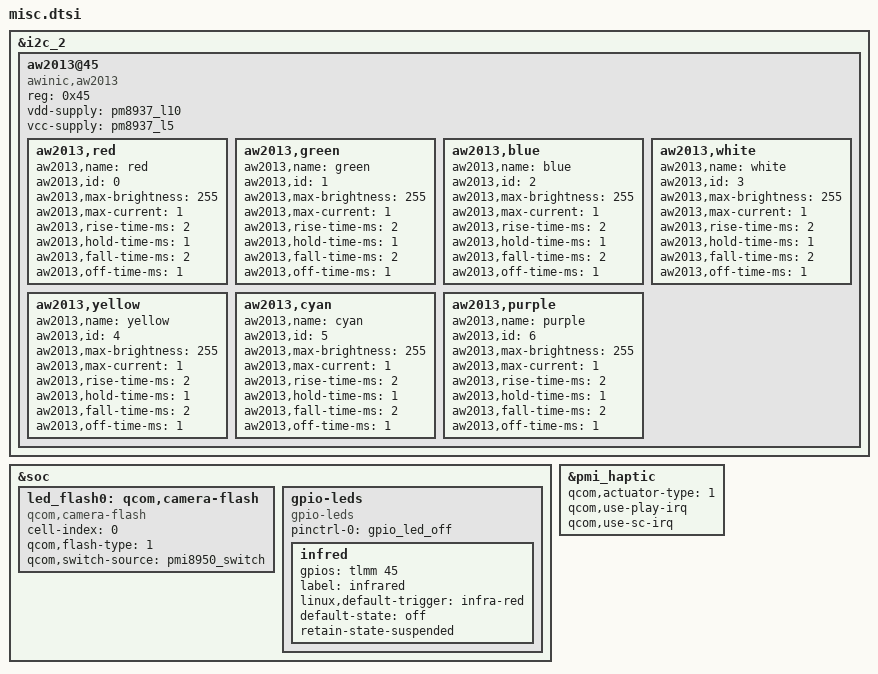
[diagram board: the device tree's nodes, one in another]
/* FROM: S88536AA2.dtsi */
&i2c_2  {
	aw2013@45 {
		compatible = "awinic,aw2013";
		reg = <0x45>;
		vdd-supply = <&pm8937_l10>; //Power supply needed to power up the device
		vcc-supply = <&pm8937_l5>; //Power source required to power up i2c bus

		aw2013,red {
			aw2013,name = "red";
			aw2013,id = <0>;
			aw2013,max-brightness = <255>;
			aw2013,max-current = <1>;
			aw2013,rise-time-ms = <2>;
			aw2013,hold-time-ms = <1>;
			aw2013,fall-time-ms = <2>;
			aw2013,off-time-ms = <1>;
		};
		aw2013,green {
			aw2013,name = "green";
			aw2013,id = <1>;
			aw2013,max-brightness = <255>;
			aw2013,max-current = <1>;
			aw2013,rise-time-ms = <2>;
			aw2013,hold-time-ms = <1>;
			aw2013,fall-time-ms = <2>;
			aw2013,off-time-ms = <1>;
		};
		aw2013,blue {
			aw2013,name = "blue";
			aw2013,id = <2>;
			aw2013,max-brightness = <255>;
			aw2013,max-current = <1>;
			aw2013,rise-time-ms = <2>;
			aw2013,hold-time-ms = <1>;
			aw2013,fall-time-ms = <2>;
			aw2013,off-time-ms = <1>;
		};
		aw2013,white {
			aw2013,name = "white";
			aw2013,id = <3>;
			aw2013,max-brightness = <255>;
			aw2013,max-current = <1>;
			aw2013,rise-time-ms = <2>;
			aw2013,hold-time-ms = <1>;
			aw2013,fall-time-ms = <2>;
			aw2013,off-time-ms = <1>;
		};
		aw2013,yellow {
			aw2013,name = "yellow";
			aw2013,id = <4>;
			aw2013,max-brightness = <255>;
			aw2013,max-current = <1>;
			aw2013,rise-time-ms = <2>;
			aw2013,hold-time-ms = <1>;
			aw2013,fall-time-ms = <2>;
			aw2013,off-time-ms = <1>;
		};
		aw2013,cyan {
			aw2013,name = "cyan";
			aw2013,id = <5>;
			aw2013,max-brightness = <255>;
			aw2013,max-current = <1>;
			aw2013,rise-time-ms = <2>;
			aw2013,hold-time-ms = <1>;
			aw2013,fall-time-ms = <2>;
			aw2013,off-time-ms = <1>;
		};
		aw2013,purple {
			aw2013,name = "purple";
			aw2013,id = <6>;
			aw2013,max-brightness = <255>;
			aw2013,max-current = <1>;
			aw2013,rise-time-ms = <2>;
			aw2013,hold-time-ms = <1>;
			aw2013,fall-time-ms = <2>;
			aw2013,off-time-ms = <1>;
		};
	};
};

&soc {
	led_flash0: qcom,camera-flash {
		cell-index = <0>;
		compatible = "qcom,camera-flash";
		qcom,flash-type = <1>;
		qcom,switch-source = <&pmi8950_switch>;
	};
};

&soc {
	gpio-leds {
		compatible = "gpio-leds";
		status = "okay";
		pinctrl-names = "default";
		pinctrl-0 = <&gpio_led_off>;

		infred {
			gpios = <&tlmm 45 0>;
			label = "infrared";
			linux,default-trigger = "infra-red";
			default-state = "off";
			retain-state-suspended;
		};
	};
};

/* Update qpnp-haptics configuration */
&pmi_haptic {
	qcom,actuator-type = <1>;
	qcom,use-play-irq;
	qcom,use-sc-irq;
};
